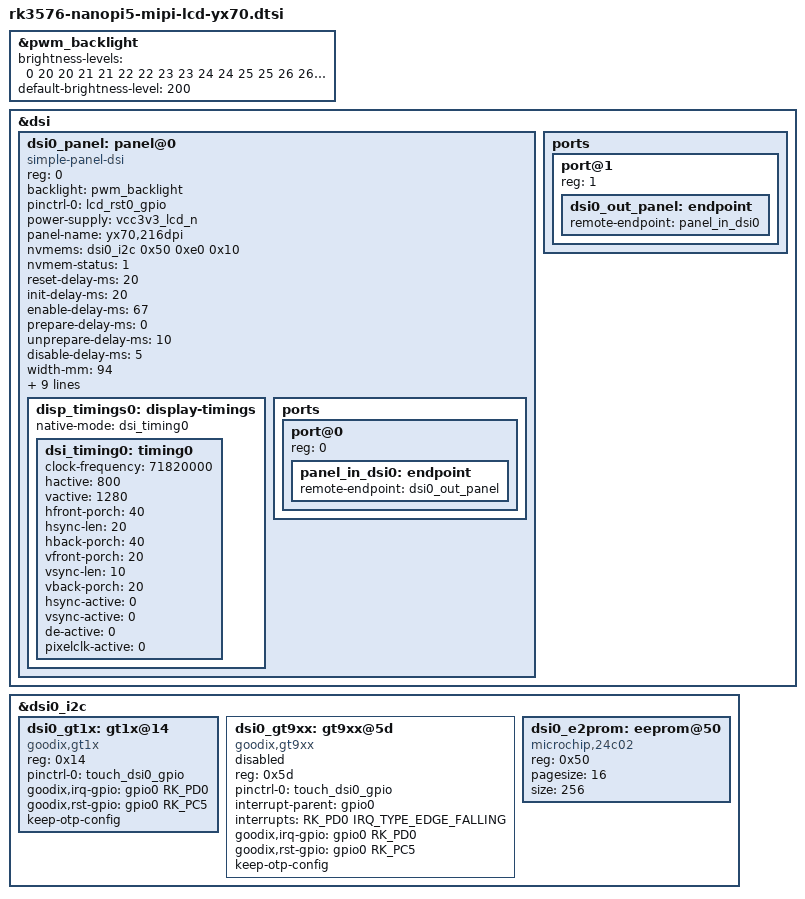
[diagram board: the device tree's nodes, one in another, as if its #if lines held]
// SPDX-License-Identifier: (GPL-2.0+ OR MIT)
/*
 * Copyright (c) 2024 FriendlyElec Computer Tech. Co., Ltd.
 * (http://www.friendlyelec.com)
 */

#define HAS_PWM_BACKLIGHT	1

&pwm_backlight {
	brightness-levels = <
		  0  20  20  21  21  22  22  23
		 23  24  24  25  25  26  26  27
		 27  28  28  29  29  30  30  31
		 31  32  32  33  33  34  34  35
		 35  36  36  37  37  38  38  39
		 40  41  42  43  44  45  46  47
		 48  49  50  51  52  53  54  55
		 56  57  58  59  60  61  62  63
		 64  65  66  67  68  69  70  71
		 72  73  74  75  76  77  78  79
		 80  81  82  83  84  85  86  87
		 88  89  90  91  92  93  94  95
		 96  97  98  99 100 101 102 103
		104 105 106 107 108 109 110 111
		112 113 114 115 116 117 118 119
		120 121 122 123 124 125 126 127
		128 129 130 131 132 133 134 135
		136 137 138 139 140 141 142 143
		144 145 146 147 148 149 150 151
		152 153 154 155 156 157 158 159
		160 161 162 163 164 165 166 167
		168 169 170 171 172 173 174 175
		176 177 178 179 180 181 182 183
		184 185 186 187 188 189 190 191
		192 193 194 195 196 197 198 199
		200 201 202 203 204 205 206 207
		208 209 210 211 212 213 214 215
		216 217 218 219 220 221 222 223
		224 225 226 227 228 229 230 231
		232 233 234 235 236 237 238 239
		240 241 242 243 244 245 246 247
		248 249 250 251 252 253 254 255
	>;
	default-brightness-level = <200>;
};

#if defined(ENABLE_MIPI_DSI0)
&dsi {
	dsi0_panel: panel@0 {
		compatible = "simple-panel-dsi";
		reg = <0>;

		backlight = <&pwm_backlight>;
		pinctrl-names = "default";
		pinctrl-0 = <&lcd_rst0_gpio>;
		power-supply = <&vcc3v3_lcd_n>;
		panel-name = "yx70,216dpi";
		nvmems = <&dsi0_i2c 0x50 0xe0 0x10>;
		nvmem-status = <1>;

		reset-delay-ms = <20>;
		init-delay-ms = <20>;
		enable-delay-ms = <67>;
		prepare-delay-ms = <0>;
		unprepare-delay-ms = <10>;
		disable-delay-ms = <5>;
		width-mm = <94>;
		height-mm = <151>;

		dsi,flags = <(MIPI_DSI_MODE_VIDEO | MIPI_DSI_MODE_VIDEO_BURST |
			      MIPI_DSI_MODE_LPM)>;
		dsi,format = <MIPI_DSI_FMT_RGB888>;
		dsi,lanes  = <4>;
		panel-init-sequence = [
			39 00 04 FF 98 81 03
			15 00 02 01 00
			15 00 02 02 00
			15 00 02 03 53
			15 00 02 04 53
			15 00 02 05 13
			15 00 02 06 04
			15 00 02 07 02
			15 00 02 08 02
			15 00 02 09 00
			15 00 02 0A 00
			15 00 02 0B 00
			15 00 02 0C 00
			15 00 02 0D 00
			15 00 02 0E 00
			15 00 02 0F 00
			15 00 02 10 00
			15 00 02 11 00
			15 00 02 12 00
			15 00 02 13 00
			15 00 02 14 00
			15 00 02 15 00
			15 00 02 16 00
			15 00 02 17 00
			15 00 02 18 00
			15 00 02 19 00
			15 00 02 1A 00
			15 00 02 1B 00
			15 00 02 1C 00
			15 00 02 1D 00
			15 00 02 1E C0
			15 00 02 1F 80
			15 00 02 20 02
			15 00 02 21 09
			15 00 02 22 00
			15 00 02 23 00
			15 00 02 24 00
			15 00 02 25 00
			15 00 02 26 00
			15 00 02 27 00
			15 00 02 28 55
			15 00 02 29 03
			15 00 02 2A 00
			15 00 02 2B 00
			15 00 02 2C 00
			15 00 02 2D 00
			15 00 02 2E 00
			15 00 02 2F 00
			15 00 02 30 00
			15 00 02 31 00
			15 00 02 32 00
			15 00 02 33 00
			15 00 02 34 00
			15 00 02 35 00
			15 00 02 36 00
			15 00 02 37 00
			15 00 02 38 3C
			15 00 02 39 00
			15 00 02 3A 00
			15 00 02 3B 00
			15 00 02 3C 00
			15 00 02 3D 00
			15 00 02 3E 00
			15 00 02 3F 00
			15 00 02 40 00
			15 00 02 41 00
			15 00 02 42 00
			15 00 02 43 00
			15 00 02 44 00
			15 00 02 50 01
			15 00 02 51 23
			15 00 02 52 45
			15 00 02 53 67
			15 00 02 54 89
			15 00 02 55 AB
			15 00 02 56 01
			15 00 02 57 23
			15 00 02 58 45
			15 00 02 59 67
			15 00 02 5A 89
			15 00 02 5B AB
			15 00 02 5C CD
			15 00 02 5D EF
			15 00 02 5E 01
			15 00 02 5F 02
			15 00 02 60 02
			15 00 02 61 08
			15 00 02 62 02
			15 00 02 63 02
			15 00 02 64 0A
			15 00 02 65 15
			15 00 02 66 14
			15 00 02 67 11
			15 00 02 68 10
			15 00 02 69 0F
			15 00 02 6A 0E
			15 00 02 6B 0D
			15 00 02 6C 0C
			15 00 02 6D 06
			15 00 02 6E 02
			15 00 02 6F 02
			15 00 02 70 02
			15 00 02 71 02
			15 00 02 72 02
			15 00 02 73 02
			15 00 02 74 02
			15 00 02 75 02
			15 00 02 76 02
			15 00 02 77 06
			15 00 02 78 02
			15 00 02 79 02
			15 00 02 7A 0A
			15 00 02 7B 15
			15 00 02 7C 14
			15 00 02 7D 10
			15 00 02 7E 11
			15 00 02 7F 0C
			15 00 02 80 0D
			15 00 02 81 0E
			15 00 02 82 0F
			15 00 02 83 08
			15 00 02 84 02
			15 00 02 85 02
			15 00 02 86 02
			15 00 02 87 02
			15 00 02 88 02
			15 00 02 89 02
			15 00 02 8A 02
			39 00 04 FF 98 81 04
			15 00 02 6C 15
			15 00 02 6E 30
			15 00 02 6F 37
			15 00 02 8D 1F
			15 00 02 87 BA
			15 00 02 26 76
			15 00 02 B2 D1
			15 00 02 B5 07
			15 00 02 35 17
			15 00 02 33 14
			15 00 02 31 75
			15 00 02 3A 85
			15 00 02 3B 98
			15 00 02 38 01
			15 00 02 39 00
			39 00 04 FF 98 81 01
			15 00 02 22 0A
			15 00 02 31 00
			15 00 02 50 E9
			15 00 02 51 E4
			15 00 02 53 58
			15 00 02 55 64
			15 00 02 60 28
			15 00 02 2E C8
			15 00 02 34 01
			15 00 02 A0 00
			15 00 02 A1 13
			15 00 02 A2 24
			15 00 02 A3 15
			15 00 02 A4 18
			15 00 02 A5 2F
			15 00 02 A6 22
			15 00 02 A7 21
			15 00 02 A8 89
			15 00 02 A9 1B
			15 00 02 AA 27
			15 00 02 AB 7D
			15 00 02 AC 1B
			15 00 02 AD 1B
			15 00 02 AE 50
			15 00 02 AF 24
			15 00 02 B0 2A
			15 00 02 B1 51
			15 00 02 B2 5A
			15 00 02 B3 1B
			15 00 02 C0 00
			15 00 02 C1 16
			15 00 02 C2 24
			15 00 02 C3 13
			15 00 02 C4 18
			15 00 02 C5 2A
			15 00 02 C6 20
			15 00 02 C7 22
			15 00 02 C8 80
			15 00 02 C9 1C
			15 00 02 CA 28
			15 00 02 CB 71
			15 00 02 CC 1D
			15 00 02 CD 1B
			15 00 02 CE 51
			15 00 02 CF 24
			15 00 02 D0 2A
			15 00 02 D1 4C
			15 00 02 D2 5A
			15 00 02 D3 32
			39 00 04 FF 98 81 02
			15 00 02 04 17
			15 00 02 05 12
			15 00 02 06 40
			15 00 02 07 0B
			39 00 04 FF 98 81 00
			05 78 01 11
			05 1E 01 29
		];

		panel-exit-sequence = [
			15 00 02 28 00
			15 3C 02 10 00
		];

		disp_timings0: display-timings {
			native-mode = <&dsi_timing0>;
			dsi_timing0: timing0 {
				clock-frequency = <71820000>;
				hactive = <800>;
				vactive = <1280>;
				hfront-porch = <40>;
				hsync-len = <20>;
				hback-porch = <40>;
				vfront-porch = <20>;
				vsync-len = <10>;
				vback-porch = <20>;
				hsync-active = <0>;
				vsync-active = <0>;
				de-active = <0>;
				pixelclk-active = <0>;
			};
		};

		ports {
			#address-cells = <1>;
			#size-cells = <0>;

			port@0 {
				reg = <0>;
				panel_in_dsi0: endpoint {
					remote-endpoint = <&dsi0_out_panel>;
				};
			};
		};
	};

	ports {
		#address-cells = <1>;
		#size-cells = <0>;

		port@1 {
			reg = <1>;
			dsi0_out_panel: endpoint {
				remote-endpoint = <&panel_in_dsi0>;
			};
		};
	};
};

&dsi0_i2c {
	dsi0_gt1x: gt1x@14 {
		compatible = "goodix,gt1x";
		reg = <0x14>;
		pinctrl-names = "default";
		pinctrl-0 = <&touch_dsi0_gpio>;
		goodix,irq-gpio = <&gpio0 RK_PD0 IRQ_TYPE_LEVEL_LOW>;
		goodix,rst-gpio = <&gpio0 RK_PC5 GPIO_ACTIVE_HIGH>;
		keep-otp-config;
	};

	dsi0_gt9xx: gt9xx@5d {
		compatible = "goodix,gt9xx";
		reg = <0x5d>;
		pinctrl-names = "default";
		pinctrl-0 = <&touch_dsi0_gpio>;
		interrupt-parent = <&gpio0>;
		interrupts = <RK_PD0 IRQ_TYPE_EDGE_FALLING>;
		goodix,irq-gpio = <&gpio0 RK_PD0 IRQ_TYPE_LEVEL_LOW>;
		goodix,rst-gpio = <&gpio0 RK_PC5 GPIO_ACTIVE_HIGH>;
		keep-otp-config;
		status = "disabled";
	};

	dsi0_e2prom: eeprom@50 {
		compatible = "microchip,24c02", "atmel,24c02";
		reg = <0x50>;
		#address-cells = <2>;
		#size-cells = <0>;
		pagesize = <16>;
		size = <256>;
	};
};
#endif
